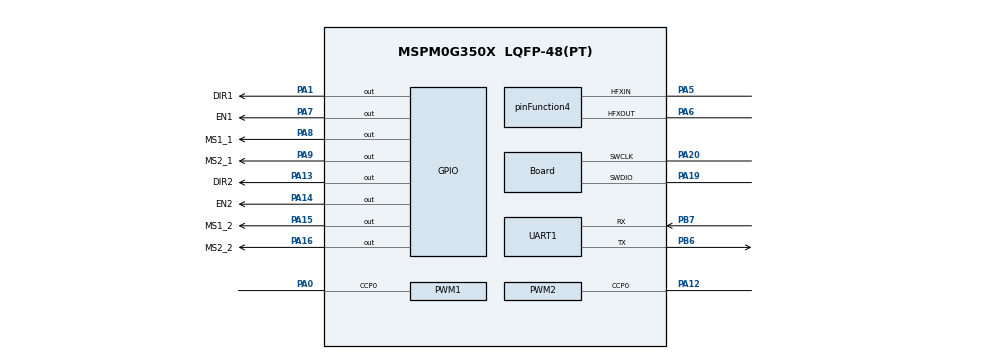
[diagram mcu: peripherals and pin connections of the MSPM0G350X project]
/**
 * TMC2209 dual stepper — pin map aligned with apps/gimbal
 * @cliArgs --device "MSPM0G350X" --part "Default" --package "LQFP-48(PT)" --product "mspm0_sdk@2.05.01.00"
 * @versions {"tool":"1.24.1+4189"}
 */

/**
 * Import the modules used in this configuration.
 */
const GPIO   = scripting.addModule("/ti/driverlib/GPIO", {}, false);
const GPIO1  = GPIO.addInstance();
const GPIO2  = GPIO.addInstance();
const PWM    = scripting.addModule("/ti/driverlib/PWM", {}, false);
const PWM1   = PWM.addInstance();
const PWM2   = PWM.addInstance();
const SYSCTL = scripting.addModule("/ti/driverlib/SYSCTL");
const UART   = scripting.addModule("/ti/driverlib/UART", {}, false);
const UART1  = UART.addInstance();

/**
 * Write custom configuration values to the imported modules.
 */
const divider9       = system.clockTree["UDIV"];
divider9.divideValue = 2;

const multiplier2         = system.clockTree["PLL_QDIV"];
multiplier2.multiplyValue = 5;

const mux4       = system.clockTree["EXHFMUX"];
mux4.inputSelect = "EXHFMUX_XTAL";

const mux8       = system.clockTree["HSCLKMUX"];
mux8.inputSelect = "HSCLKMUX_SYSPLL0";

const pinFunction4                        = system.clockTree["HFXT"];
pinFunction4.inputFreq                    = 40;
pinFunction4.enable                       = true;
pinFunction4.peripheral.$assign           = "SYSCTL";
pinFunction4.peripheral.hfxInPin.$assign  = "PA5";
pinFunction4.peripheral.hfxOutPin.$assign = "PA6";

/*
 * TMC2209 电机1 (Yaw)
 *   PA0  STEP  (TIMA0 PWM)
 *   PA1  DIR
 *   PA7  EN    (低有效)
 *   PA8  MS1
 *   PA9  MS2
 */
GPIO1.$name                         = "TMC1";
GPIO1.port                          = "PORTA";
GPIO1.associatedPins.create(4);
GPIO1.associatedPins[0].$name       = "DIR1";
GPIO1.associatedPins[0].pin.$assign = "PA1";
GPIO1.associatedPins[1].$name       = "EN1";
GPIO1.associatedPins[1].pin.$assign = "PA7";
GPIO1.associatedPins[2].$name       = "MS1_1";
GPIO1.associatedPins[2].pin.$assign = "PA8";
GPIO1.associatedPins[3].$name       = "MS2_1";
GPIO1.associatedPins[3].pin.$assign = "PA9";

const Board                       = scripting.addModule("/ti/driverlib/Board", {}, false);
Board.peripheral.$assign          = "DEBUGSS";
Board.peripheral.swclkPin.$assign = "PA20";
Board.peripheral.swdioPin.$assign = "PA19";

/*
 * TMC2209 电机2 (Pitch)
 *   PA12 STEP  (TIMG0 PWM)
 *   PA13 DIR
 *   PA14 EN
 *   PA15 MS1
 *   PA16 MS2
 */
GPIO2.$name                         = "TMC2";
GPIO2.port                          = "PORTA";
GPIO2.associatedPins.create(4);
GPIO2.associatedPins[0].$name       = "DIR2";
GPIO2.associatedPins[0].pin.$assign = "PA13";
GPIO2.associatedPins[1].$name       = "EN2";
GPIO2.associatedPins[1].pin.$assign = "PA14";
GPIO2.associatedPins[2].$name       = "MS1_2";
GPIO2.associatedPins[2].pin.$assign = "PA15";
GPIO2.associatedPins[3].$name       = "MS2_2";
GPIO2.associatedPins[3].pin.$assign = "PA16";

PWM1.$name                              = "TMC_PWM1";
PWM1.ccIndex                            = [0];
PWM1.clockDivider                       = 8;
PWM1.timerCount                         = 10000;
PWM1.pwmMode                            = "EDGE_ALIGN_UP";
PWM1.interrupts                         = ["LOAD_EVENT"];
PWM1.PWM_CHANNEL_0.$name                = "ti_driverlib_pwm_PWMTimerCC1";
PWM1.PWM_CHANNEL_0.dutyCycle            = 50;
PWM1.ccp0PinConfig.direction            = scripting.forceWrite("OUTPUT");
PWM1.ccp0PinConfig.hideOutputInversion  = scripting.forceWrite(false);
PWM1.ccp0PinConfig.onlyInternalResistor = scripting.forceWrite(false);
PWM1.ccp0PinConfig.passedPeripheralType = scripting.forceWrite("Digital");
PWM1.ccp0PinConfig.$name                = "ti_driverlib_gpio_GPIOPinGeneric5";
PWM1.peripheral.$assign                 = "TIMA0";
PWM1.peripheral.ccp0Pin.$assign         = "PA0";

PWM2.$name                              = "TMC_PWM2";
PWM2.ccIndex                            = [0];
PWM2.clockDivider                       = 8;
PWM2.timerCount                         = 10000;
PWM2.pwmMode                            = "EDGE_ALIGN_UP";
PWM2.interrupts                         = ["LOAD_EVENT"];
PWM2.PWM_CHANNEL_0.$name                = "ti_driverlib_pwm_PWMTimerCC0";
PWM2.PWM_CHANNEL_0.dutyCycle            = 50;
PWM2.ccp0PinConfig.$name                = "ti_driverlib_gpio_GPIOPinGeneric4";
PWM2.ccp0PinConfig.direction            = scripting.forceWrite("OUTPUT");
PWM2.ccp0PinConfig.hideOutputInversion  = scripting.forceWrite(false);
PWM2.ccp0PinConfig.onlyInternalResistor = scripting.forceWrite(false);
PWM2.ccp0PinConfig.passedPeripheralType = scripting.forceWrite("Digital");
PWM2.peripheral.$assign                 = "TIMG0";
PWM2.peripheral.ccp0Pin.$assign         = "PA12";

SYSCTL.forceDefaultClkConfig = true;
SYSCTL.clockTreeEn           = true;

UART1.targetBaudRate                   = 115200;
UART1.enabledInterrupts                = ["RX"];
UART1.$name                            = "DEBUG";
UART1.peripheral.$assign               = "UART1";
UART1.peripheral.rxPin.$assign         = "PB7";
UART1.peripheral.txPin.$assign         = "PB6";
UART1.txPinConfig.direction            = scripting.forceWrite("OUTPUT");
UART1.txPinConfig.hideOutputInversion  = scripting.forceWrite(false);
UART1.txPinConfig.onlyInternalResistor = scripting.forceWrite(false);
UART1.txPinConfig.passedPeripheralType = scripting.forceWrite("Digital");
UART1.txPinConfig.$name                = "ti_driverlib_gpio_GPIOPinGeneric6";
UART1.rxPinConfig.hideOutputInversion  = scripting.forceWrite(false);
UART1.rxPinConfig.onlyInternalResistor = scripting.forceWrite(false);
UART1.rxPinConfig.passedPeripheralType = scripting.forceWrite("Digital");
UART1.rxPinConfig.$name                = "ti_driverlib_gpio_GPIOPinGeneric7";

const ProjectConfig              = scripting.addModule("/ti/project_config/ProjectConfig", {}, false);
ProjectConfig.migrationCondition = true;
